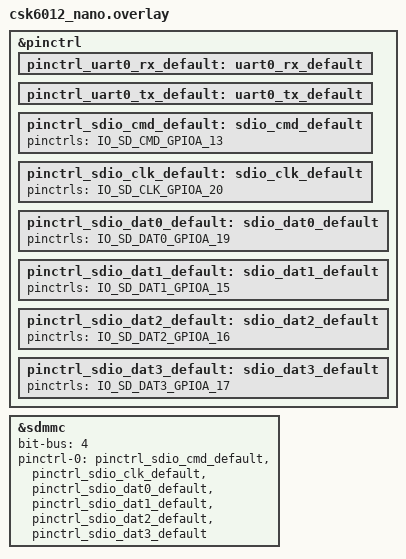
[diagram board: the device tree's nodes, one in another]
/*
 * Copyright (c) 2023 Anhui(Shenzhen) Listenai Co., Ltd.
 *
 * SPDX-License-Identifier: Apache-2.0
 */
 &pinctrl {
	/* UART alternate function */
	pinctrl_uart0_rx_default: uart0_rx_default{
	};

	pinctrl_uart0_tx_default: uart0_tx_default{
	};

	/* SDIO alternate function */
	pinctrl_sdio_cmd_default: sdio_cmd_default{
		pinctrls = <IO_SD_CMD_GPIOA_13>;
	};

	pinctrl_sdio_clk_default: sdio_clk_default{
		pinctrls = <IO_SD_CLK_GPIOA_20>;
	};

	pinctrl_sdio_dat0_default: sdio_dat0_default{
		pinctrls = <IO_SD_DAT0_GPIOA_19>;
	};

	pinctrl_sdio_dat1_default: sdio_dat1_default{
		pinctrls = <IO_SD_DAT1_GPIOA_15>;
	};

	pinctrl_sdio_dat2_default: sdio_dat2_default{
		pinctrls = <IO_SD_DAT2_GPIOA_16>;
	};

	pinctrl_sdio_dat3_default: sdio_dat3_default{
		pinctrls = <IO_SD_DAT3_GPIOA_17>;
	};
};

&sdmmc {
	status = "okay";
	bit-bus = <4>;
	pinctrl-0 = <
	&pinctrl_sdio_cmd_default
	&pinctrl_sdio_clk_default
	&pinctrl_sdio_dat0_default
	&pinctrl_sdio_dat1_default
	&pinctrl_sdio_dat2_default
	&pinctrl_sdio_dat3_default
	>;
	pinctrl-names = "default";
};
